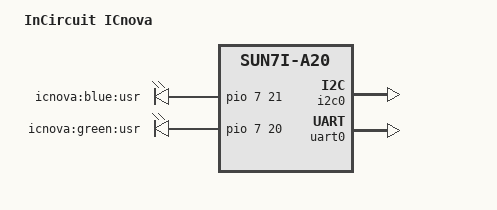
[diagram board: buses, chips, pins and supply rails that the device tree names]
/*
 * Copyright 2015 Maxime Ripard
 *
 * Maxime Ripard <maxime.ripard@free-electrons.com>
 *
 * This file is dual-licensed: you can use it either under the terms
 * of the GPL or the X11 license, at your option. Note that this dual
 * licensing only applies to this file, and not this project as a
 * whole.
 *
 *  a) This file is free software; you can redistribute it and/or
 *     modify it under the terms of the GNU General Public License as
 *     published by the Free Software Foundation; either version 2 of the
 *     License, or (at your option) any later version.
 *
 *     This file is distributed in the hope that it will be useful,
 *     but WITHOUT ANY WARRANTY; without even the implied warranty of
 *     MERCHANTABILITY or FITNESS FOR A PARTICULAR PURPOSE.  See the
 *     GNU General Public License for more details.
 *
 * Or, alternatively,
 *
 *  b) Permission is hereby granted, free of charge, to any person
 *     obtaining a copy of this software and associated documentation
 *     files (the "Software"), to deal in the Software without
 *     restriction, including without limitation the rights to use,
 *     copy, modify, merge, publish, distribute, sublicense, and/or
 *     sell copies of the Software, and to permit persons to whom the
 *     Software is furnished to do so, subject to the following
 *     conditions:
 *
 *     The above copyright notice and this permission notice shall be
 *     included in all copies or substantial portions of the Software.
 *
 *     THE SOFTWARE IS PROVIDED "AS IS", WITHOUT WARRANTY OF ANY KIND,
 *     EXPRESS OR IMPLIED, INCLUDING BUT NOT LIMITED TO THE WARRANTIES
 *     OF MERCHANTABILITY, FITNESS FOR A PARTICULAR PURPOSE AND
 *     NONINFRINGEMENT. IN NO EVENT SHALL THE AUTHORS OR COPYRIGHT
 *     HOLDERS BE LIABLE FOR ANY CLAIM, DAMAGES OR OTHER LIABILITY,
 *     WHETHER IN AN ACTION OF CONTRACT, TORT OR OTHERWISE, ARISING
 *     FROM, OUT OF OR IN CONNECTION WITH THE SOFTWARE OR THE USE OR
 *     OTHER DEALINGS IN THE SOFTWARE.
 */

/dts-v1/;
#include "sun7i-a20.dtsi"
#include "sunxi-common-regulators.dtsi"

#include <dt-bindings/gpio/gpio.h>
#include <dt-bindings/interrupt-controller/irq.h>
#include <dt-bindings/pinctrl/sun4i-a10.h>

/ {
	model = "InCircuit ICnova";
	compatible = "incircuit,a20-icnova", "allwinner,sun7i-a20";

	aliases {
		serial0 = &uart0;
	};

	chosen {
		stdout-path = "serial0:115200n8";
	};

	leds {
		compatible = "gpio-leds";
		pinctrl-names = "default";
		pinctrl-0 = <&leds_pins_icnova>;

		blue {
			label = "icnova:blue:usr";
			gpios = <&pio 7 21 GPIO_ACTIVE_HIGH>;
		};

		green {
			label = "icnova:green:usr";
			gpios = <&pio 7 20 GPIO_ACTIVE_HIGH>;
		};
	};

	sound {
		compatible = "simple-audio-card";
		simple-audio-card,format = "i2s";
		simple-audio-card,routing =
			"Headphone Jack", "VOUTLHP",
			"Headphone Jack", "VOUTRHP",
			"Line Out Jack", "VOUTL",
			"Line Out Jack", "VOUTR",
			"VINM", "Mic Jack",
			"VINL", "Line In Jack",
			"VINR", "Line In Jack";
		simple-audio-card,widgets =
			"Headphone", "Headphone Jack",
			"Line", "Line In Jack",
			"Line", "Line Out Jack",
			"Microphone", "Mic Jack";

		simple-audio-card,cpu {
			sound-dai = <&dai0>;
		};

		simple-audio-card,codec {
			sound-dai = <&codec>;
		};
	};
};

&i2c0 {
	pinctrl-names = "default";
	pinctrl-0 = <&i2c0_pins_a>;
	status = "okay";
};

&pio {
	leds_pins_icnova: led_pins@0 {
		allwinner,pins = "PH20", "PH21";
		allwinner,function = "gpio_out";
		allwinner,drive = <SUN4I_PINCTRL_10_MA>;
		allwinner,pull = <SUN4I_PINCTRL_NO_PULL>;
	};
};

&uart0 {
	pinctrl-names = "default";
	pinctrl-0 = <&uart0_pins_a>;
	status = "okay";
};
